# ESP32-S31 register map
Vendor: ESPRESSIF SYSTEMS (SHANGHAI) CO., LTD.; Series: ESP32 S-Series; File version: 1
CPU: RV32IMAFC r0p0, little endian, no MPU, FPU, 0 interrupt priority bits
Address unit: 32 bits
Registers are 32-bit, read-write, reset 0x0 unless marked. A register's access mark holds for its fields unless they carry their own. Offsets are from the block's base; [hi:lo] are bit positions; {n}, {i} and the like mark numbered series.

## LP_WDT — Low-power Watchdog Timer
Base 0x20801000
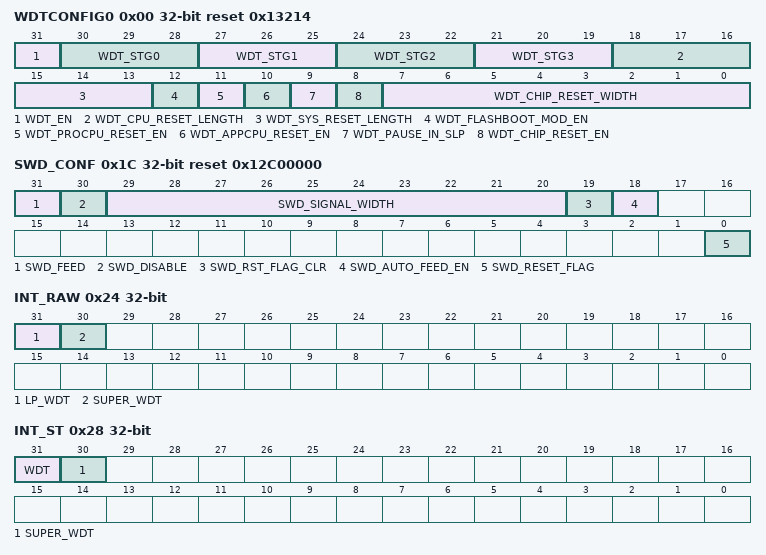
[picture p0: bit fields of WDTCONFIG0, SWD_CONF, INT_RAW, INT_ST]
0x00 WDTCONFIG0 reset 0x13214 — need_des
  [31] WDT_EN — need_des
  [30-3n:28-3n] WDT_STG{n} (n=0..3) — need_des
  [18:16] WDT_CPU_RESET_LENGTH — need_des
  [15:13] WDT_SYS_RESET_LENGTH — need_des
  [12] WDT_FLASHBOOT_MOD_EN — need_des
  [11] WDT_PROCPU_RESET_EN — need_des
  [10] WDT_APPCPU_RESET_EN — need_des
  [9] WDT_PAUSE_IN_SLP — need_des
  [8] WDT_CHIP_RESET_EN — need_des
  [7:0] WDT_CHIP_RESET_WIDTH — need_des
{0x0+4i} WDTCONFIG{i} (i=1..4) reset 0x30D40 — WDT configuration register
  [31:0] HOLD — need_des
0x14 WDTFEED wo — need_des
  [31] WDT_FEED
0x18 WDTWPROTECT — need_des
  [31:0] WDT_WKEY
0x1C SWD_CONF access per field reset 0x12C00000 — need_des
  [31] SWD_FEED wo — need_des
  [30] SWD_DISABLE rw — need_des
  [29:20] SWD_SIGNAL_WIDTH rw — need_des
  [19] SWD_RST_FLAG_CLR wo — need_des
  [18] SWD_AUTO_FEED_EN rw — need_des
  [0] SWD_RESET_FLAG ro — need_des
0x20 SWD_WPROTECT — need_des
  [31:0] SWD_WKEY
0x24 INT_RAW — need_des
  [31] LP_WDT — need_des
  [30] SUPER_WDT — need_des
0x28 INT_ST ro — need_des
  [31] WDT — need_des
  [30] SUPER_WDT — need_des
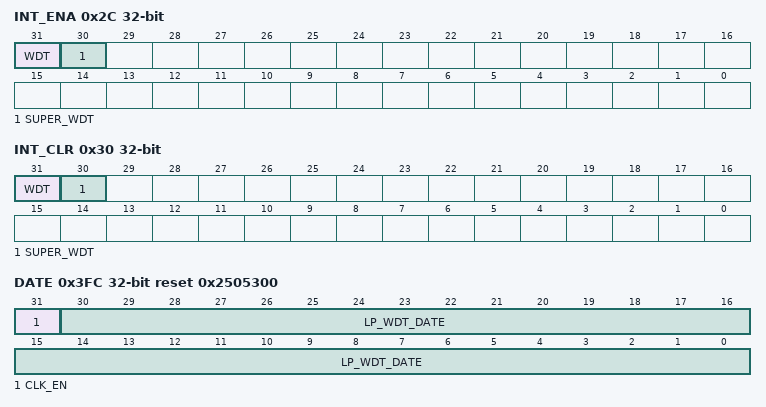
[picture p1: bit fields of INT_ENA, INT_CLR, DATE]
0x2C INT_ENA — need_des
  [31] WDT — need_des
  [30] SUPER_WDT — need_des
0x30 INT_CLR wo — need_des
  [31] WDT write-1-clears — need_des
  [30] SUPER_WDT write-1-clears — need_des
0x34 PAUSE_EN reset 0x80000000 — need_des
  [31] PAUSE_EN
0x3FC DATE reset 0x2505300 — need_des
  [31] CLK_EN — need_des
  [30:0] LP_WDT_DATE — need_des

## SHA — SHA (Secure Hash Algorithm) Accelerator
Base 0x20509000
0x00 MODE reset 0x2 — Configures SHA algorithm
  [3:0] MODE — Configures the SHA algorithm. \\ 0: SHA-1\\ 1: SHA2-224\\ 2: SHA2-256\\ 3: SHA2-384\\ 4: SHA2-512\\ 5: SHA2-512/224\\ 6: SHA2-512/256\\ 7: SHA2-512/t\\ 8: SHA3-224\\ 9: SHA3-256\\ 10: SHA3-384\\ 11: SHA3-512\\ 12: SHAKE128\\ 13: SHAKE256\\ 14: SM3\\
0x04 T_STRING — SHA 512/t configuration register 0.
  [31:0] T_STRING — Sha t_string (used if and only if mode == SHA_512/t).
0x08 T_LENGTH — SHA 512/t configuration register 1.
  [6:0] T_LENGTH — Sha t_length (used if and only if mode == SHA_512/t).
0x0C DMA_BLOCK_NUM — Block number register (only effective for DMA-SHA)
  [15:0] DMA_BLOCK_NUM — Configures the DMA-SHA block number.
0x10 START wo — Starts the SHA accelerator for Typical SHA operation
  [0] START — Write 1 to start Typical SHA calculation.
0x14 CONTINUE wo — Continues SHA operation (only effective in Typical SHA mode)
  [0] CONTINUE — Write 1 to continue Typical SHA calculation.
0x18 BUSY ro — Represents if SHA Accelerator is busy or not
  [0] STATE — Represents the states of SHA accelerator. \\ 0: idle\\ 1: busy\\
0x1C DMA_START wo — Starts the SHA accelerator for DMA-SHA operation
  [0] DMA_START — Write 1 to start DMA-SHA calculation.
0x20 DMA_CONTINUE wo — Continues SHA operation (only effective in DMA-SHA mode)
  [0] DMA_CONTINUE — Write 1 to continue DMA-SHA calculation.
0x24 CLEAR_IRQ wo — DMA-SHA interrupt clear register
  [0] CLEAR_INTERRUPT — Write 1 to clear DMA-SHA interrupt.
0x28 IRQ_ENA — DMA-SHA interrupt enable register
  [0] INTERRUPT_ENA — Write 1 to enable DMA-SHA interrupt.
0x2C DATE reset 0x20250623 — Version control register
  [29:0] DATE — Version control register.
0x30 DMA_RX_RESET wo — DMA RX FIFO Reset Signal
  [0] DMA_RX_RESET — Write 1 to reset DMA RX FIFO
0x34 DMA_TX_RESET wo — DMA TX FIFO Reset Signal
  [0] DMA_TX_RESET — Write 1 to reset DMA TX FIFO
0x38 FREE reset 0x1 — SHA free state
  [0] FREE — Represents if SHA Accelerator is free or not. \\ 0: non-free\\ 1: free\\
0x3C SHA3_SHAKE_LENGTH reset 0x32 — DMA configuration register 3.
  [20:0] SHAKE_LENGTH — SHAKE output hash word length
{0x40+4i} H_MEM[{i}] (i=0..15) access not given — SHA1, SHA2-256, SM3 H memory which contains intermediate hash or final hash. \\ SHA1, SHA2-256, SM3 : 0x00~0x20 (R/W) \\ SHA2-512 : 0x00~0x40 (R/W) \\
{0x80+4i} M_MEM[{i}] (i=0..31) access not given — SHA1, SHA2-256, SM3 M memory which contains message. \\ SHA1, SHA2-256, SM3 : 0x00~0x40 \\ SHA2-512 : 0x00~0x80 \\
{0x100+4i} SHA3_H_MEM[{i}] (i=0..49) access not given — SHA3, SHAKE H memory which contains intermediate hash or final hash.
{0x200+4i} SHA3_M_MEM[{i}] (i=0..49) access not given — SHA3, SHAKE M memory which contains message.
